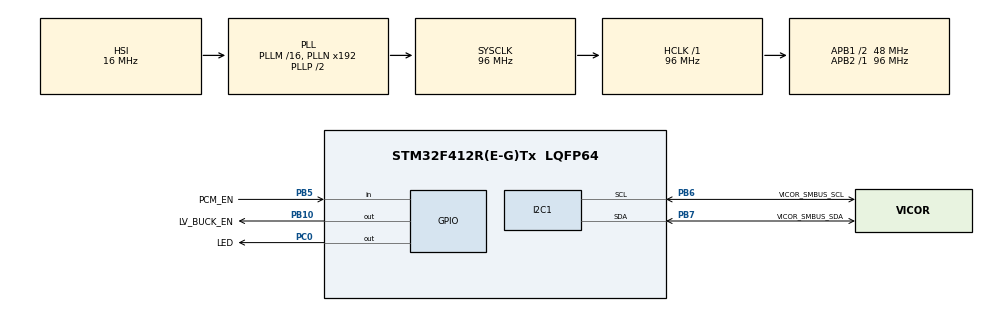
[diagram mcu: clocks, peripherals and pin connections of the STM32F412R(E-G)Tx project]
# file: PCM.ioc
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FREERTOS.INCLUDE_uxTaskGetStackHighWaterMark2=1
FREERTOS.INCLUDE_xTaskGetHandle=1
FREERTOS.Tasks01=vicorTask,24,512,StartVictorTask,Default,NULL,Static,vicorTaskBuffer,vicorTaskControlBlock
Mcu.Family=STM32F4
Mcu.Name=STM32F412R(E-G)Tx
Mcu.Package=LQFP64
NVIC.I2C1_ER_IRQn=true\:5\:0\:false\:false\:true\:true\:true\:true\:true
NVIC.I2C1_EV_IRQn=true\:5\:0\:false\:false\:true\:true\:true\:true\:true
NVIC.PriorityGroup=NVIC_PRIORITYGROUP_4
PA13.GPIO_Label=SWDIO
PA13.Mode=Trace_Asynchronous_SW
PA13.Signal=SYS_JTMS-SWDIO
PA14.GPIO_Label=SWCLK
PA14.Mode=Trace_Asynchronous_SW
PA14.Signal=SYS_JTCK-SWCLK
PB10.GPIO_Label=LV_BUCK_EN
PB10.Signal=GPIO_Output
PB3.GPIO_Label=SWO
PB3.Mode=Trace_Asynchronous_SW
PB3.Signal=SYS_JTDO-SWO
PB5.GPIO_Label=PCM_EN
PB5.Signal=GPIO_Input
PB6.GPIO_Label=VICOR_SMBUS_SCL
PB6.Mode=I2C
PB6.Signal=I2C1_SCL
PB7.GPIO_Label=VICOR_SMBUS_SDA
PB7.Mode=I2C
PB7.Signal=I2C1_SDA
PC0.GPIO_Label=LED
PC0.Signal=GPIO_Output
ProjectManager.HeapSize=0x200
ProjectManager.StackSize=0x400
ProjectManager.TargetToolchain=Makefile
RCC.AHBFreq_Value=96000000
RCC.APB1CLKDivider=RCC_HCLK_DIV2
RCC.APB1Freq_Value=48000000
RCC.APB1TimFreq_Value=96000000
RCC.APB2Freq_Value=96000000
RCC.APB2TimFreq_Value=96000000
RCC.CortexFreq_Value=96000000
RCC.HCLKFreq_Value=96000000
RCC.SYSCLKFreq_VALUE=96000000
RCC.SYSCLKSource=RCC_SYSCLKSOURCE_PLLCLK
RCC.USBFreq_Value=96000000
RCC.VCOOutputFreq_Value=192000000
STMicroelectronics.X-CUBE-SMBUS.2.1.0.SMB_master=1
VP_FREERTOS_VS_CMSIS_V2.Mode=CMSIS_V2
board=custom

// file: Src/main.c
/* USER CODE BEGIN Header */
/**
 ******************************************************************************
 * @file           : main.c
 * @brief          : Main program body
 ******************************************************************************
 * @attention
 *
 * Copyright (c) 2025 STMicroelectronics.
 * All rights reserved.
 *
 * This software is licensed under terms that can be found in the LICENSE file
 * in the root directory of this software component.
 * If no LICENSE file comes with this software, it is provided AS-IS.
 *
 ******************************************************************************
 */
/* USER CODE END Header */
#include "main.h"
#include "cmsis_os.h"

/* USER CODE BEGIN Includes */
#include "tasks.h"
#include "hw/error.h"
/* USER CODE END Includes */

typedef StaticTask_t osStaticThreadDef_t;

I2C_HandleTypeDef hi2c1;

/* Definitions for vicorTask */
osThreadId_t         vicorTaskHandle;
uint32_t             vicorTaskBuffer[512];
osStaticThreadDef_t  vicorTaskControlBlock;
const osThreadAttr_t vicorTask_attributes = {
    .name       = "vicorTask",
    .cb_mem     = &vicorTaskControlBlock,
    .cb_size    = sizeof(vicorTaskControlBlock),
    .stack_mem  = &vicorTaskBuffer[0],
    .stack_size = sizeof(vicorTaskBuffer),
    .priority   = (osPriority_t)osPriorityNormal,
};

void        SystemClock_Config(void);
static void MX_GPIO_Init(void);
static void MX_I2C1_Init(void);
void        StartVictorTask(void *argument);

int main(void)
{

    /* MCU Configuration--------------------------------------------------------*/

    /* Reset of all peripherals, Initializes the Flash interface and the Systick. */
    HAL_Init();

    /* Configure the system clock */
    SystemClock_Config();

    /* Initialize all configured peripherals */
    MX_GPIO_Init();
    MX_I2C1_Init();
    /* USER CODE BEGIN 2 */
    tasks_init();
    /* USER CODE END 2 */

    /* Init scheduler */
    osKernelInitialize();

    /* Create the thread(s) */
    /* creation of vicorTask */
    vicorTaskHandle = osThreadNew(StartVictorTask, NULL, &vicorTask_attributes);

    /* Start scheduler */
    osKernelStart();

    /* We should never get here as control is now taken by the scheduler */

    /* Infinite loop */
    while (1)
    {

    }
}

void SystemClock_Config(void)
{
    RCC_OscInitTypeDef RCC_OscInitStruct = { 0 };
    RCC_ClkInitTypeDef RCC_ClkInitStruct = { 0 };

    /** Configure the main internal regulator output voltage
     */
    __HAL_RCC_PWR_CLK_ENABLE();
    __HAL_PWR_VOLTAGESCALING_CONFIG(PWR_REGULATOR_VOLTAGE_SCALE1);

    /** Initializes the RCC Oscillators according to the specified parameters
     * in the RCC_OscInitTypeDef structure.
     */
    RCC_OscInitStruct.OscillatorType      = RCC_OSCILLATORTYPE_HSI;
    RCC_OscInitStruct.HSIState            = RCC_HSI_ON;
    RCC_OscInitStruct.HSICalibrationValue = RCC_HSICALIBRATION_DEFAULT;
    RCC_OscInitStruct.PLL.PLLState        = RCC_PLL_ON;
    RCC_OscInitStruct.PLL.PLLSource       = RCC_PLLSOURCE_HSI;
    RCC_OscInitStruct.PLL.PLLM            = 16;
    RCC_OscInitStruct.PLL.PLLN            = 192;
    RCC_OscInitStruct.PLL.PLLP            = RCC_PLLP_DIV2;
    RCC_OscInitStruct.PLL.PLLQ            = 2;
    RCC_OscInitStruct.PLL.PLLR            = 2;
    if (HAL_RCC_OscConfig(&RCC_OscInitStruct) != HAL_OK)
    {
        Error_Handler();
    }

    /** Initializes the CPU, AHB and APB buses clocks
     */
    RCC_ClkInitStruct.ClockType = RCC_CLOCKTYPE_HCLK | RCC_CLOCKTYPE_SYSCLK | RCC_CLOCKTYPE_PCLK1 | RCC_CLOCKTYPE_PCLK2;
    RCC_ClkInitStruct.SYSCLKSource   = RCC_SYSCLKSOURCE_PLLCLK;
    RCC_ClkInitStruct.AHBCLKDivider  = RCC_SYSCLK_DIV1;
    RCC_ClkInitStruct.APB1CLKDivider = RCC_HCLK_DIV2;
    RCC_ClkInitStruct.APB2CLKDivider = RCC_HCLK_DIV1;

    if (HAL_RCC_ClockConfig(&RCC_ClkInitStruct, FLASH_LATENCY_3) != HAL_OK)
    {
        Error_Handler();
    }
}

static void MX_I2C1_Init(void)
{

    hi2c1.Instance             = I2C1;
    hi2c1.Init.ClockSpeed      = 100000;
    hi2c1.Init.DutyCycle       = I2C_DUTYCYCLE_2;
    hi2c1.Init.OwnAddress1     = 0;
    hi2c1.Init.AddressingMode  = I2C_ADDRESSINGMODE_7BIT;
    hi2c1.Init.DualAddressMode = I2C_DUALADDRESS_DISABLE;
    hi2c1.Init.OwnAddress2     = 0;
    hi2c1.Init.GeneralCallMode = I2C_GENERALCALL_DISABLE;
    hi2c1.Init.NoStretchMode   = I2C_NOSTRETCH_DISABLE;
    if (HAL_I2C_Init(&hi2c1) != HAL_OK)
    {
        Error_Handler();
    }
}

static void MX_GPIO_Init(void)
{
    GPIO_InitTypeDef GPIO_InitStruct = { 0 };

    /* GPIO Ports Clock Enable */
    __HAL_RCC_GPIOC_CLK_ENABLE();
    __HAL_RCC_GPIOB_CLK_ENABLE();
    __HAL_RCC_GPIOA_CLK_ENABLE();

    /*Configure GPIO pin Output Level */
    HAL_GPIO_WritePin(LED_GPIO_Port, LED_Pin, GPIO_PIN_RESET);

    /*Configure GPIO pin Output Level */
    HAL_GPIO_WritePin(LV_BUCK_EN_GPIO_Port, LV_BUCK_EN_Pin, GPIO_PIN_RESET);

    /*Configure GPIO pin : LED_Pin */
    GPIO_InitStruct.Pin   = LED_Pin;
    GPIO_InitStruct.Mode  = GPIO_MODE_OUTPUT_PP;
    GPIO_InitStruct.Pull  = GPIO_NOPULL;
    GPIO_InitStruct.Speed = GPIO_SPEED_FREQ_LOW;
    HAL_GPIO_Init(LED_GPIO_Port, &GPIO_InitStruct);

    /*Configure GPIO pin : LV_BUCK_EN_Pin */
    GPIO_InitStruct.Pin   = LV_BUCK_EN_Pin;
    GPIO_InitStruct.Mode  = GPIO_MODE_OUTPUT_PP;
    GPIO_InitStruct.Pull  = GPIO_NOPULL;
    GPIO_InitStruct.Speed = GPIO_SPEED_FREQ_LOW;
    HAL_GPIO_Init(LV_BUCK_EN_GPIO_Port, &GPIO_InitStruct);

    /*Configure GPIO pin : PCM_EN_Pin */
    GPIO_InitStruct.Pin  = PCM_EN_Pin;
    GPIO_InitStruct.Mode = GPIO_MODE_INPUT;
    GPIO_InitStruct.Pull = GPIO_NOPULL;
    HAL_GPIO_Init(PCM_EN_GPIO_Port, &GPIO_InitStruct);

}

void StartVictorTask(void *argument)
{
    /* USER CODE BEGIN 5 */
    tasks_tick();
    /* USER CODE END 5 */
}

void Error_Handler(void)
{
    __disable_irq();
    while (1)
    {
    }
}
